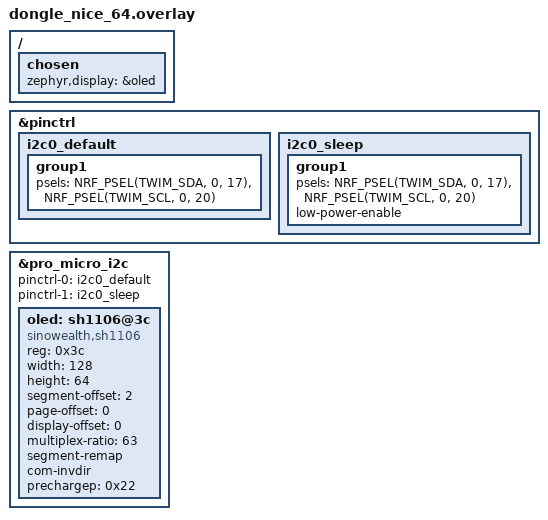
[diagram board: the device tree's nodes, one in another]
/* boards/shields/charybdis/dongle_nice_64.overlay */
#include "dongle_nice_common.dtsi"

/* ▼ 핵심: "이 oled가 바로 메인 화면입니다"라고 지정하는 부분 (이게 없어서 에러 남!) */
/ {
    chosen {
        zephyr,display = &oled;
    };
};

/* ▼ 1. 핀 번호 설정 (17, 20번 강제 고정) */
&pinctrl {
    i2c0_default: i2c0_default {
        group1 {
            psels = <NRF_PSEL(TWIM_SDA, 0, 17)>,
                    <NRF_PSEL(TWIM_SCL, 0, 20)>;
        };
    };

    i2c0_sleep: i2c0_sleep {
        group1 {
            psels = <NRF_PSEL(TWIM_SDA, 0, 17)>,
                    <NRF_PSEL(TWIM_SCL, 0, 20)>;
            low-power-enable;
        };
    };
};

/* ▼ 2. 화면 드라이버 설정 (SH1106 + 핀 적용) */
&pro_micro_i2c {
    status = "okay";
    pinctrl-0 = <&i2c0_default>;
    pinctrl-1 = <&i2c0_sleep>;
    pinctrl-names = "default", "sleep";

    oled: sh1106@3c {
        compatible = "sinowealth,sh1106";
        reg = <0x3c>;
        width = <128>;
        height = <64>;
        
        /* 화면 위치 보정 (지지직거리면 0, 밀리면 2) */
        segment-offset = <2>;
        page-offset = <0>;
        display-offset = <0>;
        
        multiplex-ratio = <63>;
        segment-remap;
        com-invdir;
        prechargep = <0x22>;
    };
};
